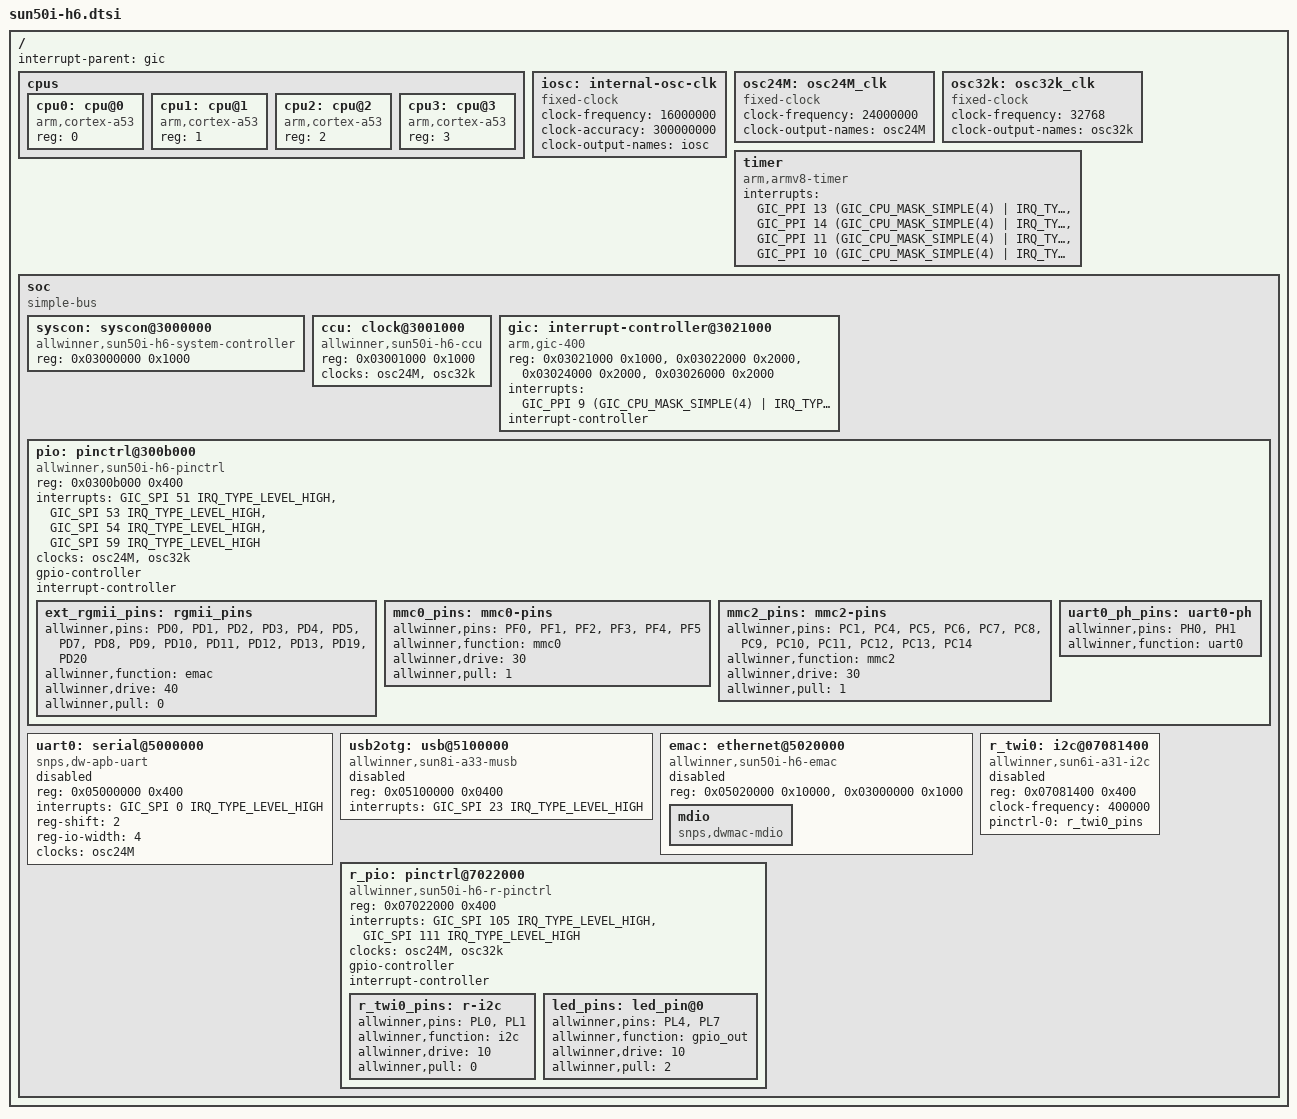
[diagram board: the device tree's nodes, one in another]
/*
 * Copyright (C) 2017 Icenowy Zheng <icenowy@aosc.io>
 *
 * This file is dual-licensed: you can use it either under the terms
 * of the GPL or the X11 license, at your option. Note that this dual
 * licensing only applies to this file, and not this project as a
 * whole.
 *
 *  a) This file is free software; you can redistribute it and/or
 *     modify it under the terms of the GNU General Public License as
 *     published by the Free Software Foundation; either version 2 of the
 *     License, or (at your option) any later version.
 *
 *     This file is distributed in the hope that it will be useful,
 *     but WITHOUT ANY WARRANTY; without even the implied warranty of
 *     MERCHANTABILITY or FITNESS FOR A PARTICULAR PURPOSE.  See the
 *     GNU General Public License for more details.
 *
 * Or, alternatively,
 *
 *  b) Permission is hereby granted, free of charge, to any person
 *     obtaining a copy of this software and associated documentation
 *     files (the "Software"), to deal in the Software without
 *     restriction, including without limitation the rights to use,
 *     copy, modify, merge, publish, distribute, sublicense, and/or
 *     sell copies of the Software, and to permit persons to whom the
 *     Software is furnished to do so, subject to the following
 *     conditions:
 *
 *     The above copyright notice and this permission notice shall be
 *     included in all copies or substantial portions of the Software.
 *
 *     THE SOFTWARE IS PROVIDED "AS IS", WITHOUT WARRANTY OF ANY KIND,
 *     EXPRESS OR IMPLIED, INCLUDING BUT NOT LIMITED TO THE WARRANTIES
 *     OF MERCHANTABILITY, FITNESS FOR A PARTICULAR PURPOSE AND
 *     NONINFRINGEMENT. IN NO EVENT SHALL THE AUTHORS OR COPYRIGHT
 *     HOLDERS BE LIABLE FOR ANY CLAIM, DAMAGES OR OTHER LIABILITY,
 *     WHETHER IN AN ACTION OF CONTRACT, TORT OR OTHERWISE, ARISING
 *     FROM, OUT OF OR IN CONNECTION WITH THE SOFTWARE OR THE USE OR
 *     OTHER DEALINGS IN THE SOFTWARE.
 */

#include <dt-bindings/interrupt-controller/arm-gic.h>

/ {
	interrupt-parent = <&gic>;
	#address-cells = <1>;
	#size-cells = <1>;

	cpus {
		#address-cells = <1>;
		#size-cells = <0>;

		cpu0: cpu@0 {
			compatible = "arm,cortex-a53", "arm,armv8";
			device_type = "cpu";
			reg = <0>;
		};

		cpu1: cpu@1 {
			compatible = "arm,cortex-a53", "arm,armv8";
			device_type = "cpu";
			reg = <1>;
		};

		cpu2: cpu@2 {
			compatible = "arm,cortex-a53", "arm,armv8";
			device_type = "cpu";
			reg = <2>;
		};

		cpu3: cpu@3 {
			compatible = "arm,cortex-a53", "arm,armv8";
			device_type = "cpu";
			reg = <3>;
		};
	};

	iosc: internal-osc-clk {
		#clock-cells = <0>;
		compatible = "fixed-clock";
		clock-frequency = <16000000>;
		clock-accuracy = <300000000>;
		clock-output-names = "iosc";
	};

	osc24M: osc24M_clk {
		#clock-cells = <0>;
		compatible = "fixed-clock";
		clock-frequency = <24000000>;
		clock-output-names = "osc24M";
	};

	osc32k: osc32k_clk {
		#clock-cells = <0>;
		compatible = "fixed-clock";
		clock-frequency = <32768>;
		clock-output-names = "osc32k";
	};


	timer {
		compatible = "arm,armv8-timer";
		interrupts = <GIC_PPI 13
			(GIC_CPU_MASK_SIMPLE(4) | IRQ_TYPE_LEVEL_HIGH)>,
			     <GIC_PPI 14
			(GIC_CPU_MASK_SIMPLE(4) | IRQ_TYPE_LEVEL_HIGH)>,
			     <GIC_PPI 11
			(GIC_CPU_MASK_SIMPLE(4) | IRQ_TYPE_LEVEL_HIGH)>,
			     <GIC_PPI 10
			(GIC_CPU_MASK_SIMPLE(4) | IRQ_TYPE_LEVEL_HIGH)>;
	};

	soc {
		compatible = "simple-bus";
		#address-cells = <1>;
		#size-cells = <1>;
		ranges;

		syscon: syscon@3000000 {
			compatible = "allwinner,sun50i-h6-system-controller",
				"syscon";
			reg = <0x03000000 0x1000>;
		};

		ccu: clock@3001000 {
			compatible = "allwinner,sun50i-h6-ccu";
			reg = <0x03001000 0x1000>;
			clocks = <&osc24M>, <&osc32k>;
			clock-names = "hosc", "losc";
			#clock-cells = <1>;
			#reset-cells = <1>;
		};

		gic: interrupt-controller@3021000 {
			compatible = "arm,gic-400";
			reg = <0x03021000 0x1000>,
			      <0x03022000 0x2000>,
			      <0x03024000 0x2000>,
			      <0x03026000 0x2000>;
			interrupts = <GIC_PPI 9 (GIC_CPU_MASK_SIMPLE(4) | IRQ_TYPE_LEVEL_HIGH)>;
			interrupt-controller;
			#interrupt-cells = <3>;
		};

		pio: pinctrl@300b000 {
			compatible = "allwinner,sun50i-h6-pinctrl";
			reg = <0x0300b000 0x400>;
			interrupts = <GIC_SPI 51 IRQ_TYPE_LEVEL_HIGH>,
				     <GIC_SPI 53 IRQ_TYPE_LEVEL_HIGH>,
				     <GIC_SPI 54 IRQ_TYPE_LEVEL_HIGH>,
				     <GIC_SPI 59 IRQ_TYPE_LEVEL_HIGH>;
			clocks = <&osc24M>, <&osc32k>;
			clock-names = "hosc", "losc";
			gpio-controller;
			#gpio-cells = <3>;
			interrupt-controller;
			#interrupt-cells = <3>;

			ext_rgmii_pins: rgmii_pins {
				allwinner,pins = "PD0", "PD1", "PD2", "PD3", "PD4",
				       "PD5", "PD7", "PD8", "PD9", "PD10",
				       "PD11", "PD12", "PD13", "PD19", "PD20";
				allwinner,function = "emac";
				allwinner,drive = <40>;
				allwinner,pull = <0>;
			};

			mmc0_pins: mmc0-pins {
				allwinner,pins = "PF0", "PF1", "PF2", "PF3",
				       "PF4", "PF5";
				allwinner,function = "mmc0";
				allwinner,drive = <30>;
				allwinner,pull = <1>;
			};

			mmc2_pins: mmc2-pins {
				allwinner,pins = "PC1", "PC4", "PC5", "PC6",
				       "PC7", "PC8", "PC9", "PC10",
				       "PC11", "PC12", "PC13", "PC14";
				allwinner,function = "mmc2";
				allwinner,drive = <30>;
				allwinner,pull = <1>;
			};

			uart0_ph_pins: uart0-ph {
				allwinner,pins = "PH0", "PH1";
				allwinner,function = "uart0";
			};
		};

		uart0: serial@5000000 {
			compatible = "snps,dw-apb-uart";
			reg = <0x05000000 0x400>;
			interrupts = <GIC_SPI 0 IRQ_TYPE_LEVEL_HIGH>;
			reg-shift = <2>;
			reg-io-width = <4>;
			clocks = <&osc24M>; /* placeholder */
			status = "disabled";
		};

		usb2otg: usb@5100000 {
			compatible = "allwinner,sun8i-a33-musb";
			reg = <0x05100000 0x0400>;
			interrupts = <GIC_SPI 23 IRQ_TYPE_LEVEL_HIGH>;
			interrupt-names = "mc";
			status = "disabled";
		};

		emac: ethernet@5020000 {
			compatible = "allwinner,sun50i-h6-emac";
			reg-names = "emac", "syscon";
			reg = <0x05020000 0x10000>, <0x03000000 0x1000>;
			#address-cells = <1>;
			#size-cells = <0>;
			status = "disabled";

			mdio: mdio {
				compatible = "snps,dwmac-mdio";
				#address-cells = <1>;
				#size-cells = <0>;
			};
		};

		r_pio: pinctrl@7022000 {
			compatible = "allwinner,sun50i-h6-r-pinctrl";
			reg = <0x07022000 0x400>;
			interrupts = <GIC_SPI 105 IRQ_TYPE_LEVEL_HIGH>,
				     <GIC_SPI 111 IRQ_TYPE_LEVEL_HIGH>;
			clocks = <&osc24M>, <&osc32k>;
			clock-names = "hosc", "losc";
			gpio-controller;
			#gpio-cells = <3>;
			interrupt-controller;
			#interrupt-cells = <3>;

			r_twi0_pins: r-i2c {
				allwinner,pins = "PL0", "PL1";
				allwinner,function = "i2c";
				allwinner,drive = <10>;
				allwinner,pull = <0>;
			};

			led_pins: led_pin@0 {
				allwinner,pins = "PL4", "PL7";
				allwinner,function = "gpio_out";
				allwinner,drive = <10>;
				allwinner,pull = <2>;
			};
		};

		r_twi0: i2c@07081400 {
			compatible = "allwinner,sun6i-a31-i2c";
			reg = <0x07081400 0x400>;
			clock-frequency = <400000>;
			pinctrl-0 = <&r_twi0_pins>;
			#address-cells = <1>;
			#size-cells = <0>;
			status = "disabled";
		};
	};
};
